VERSION ""

NS_ :

BS_:

BU_: pc mmc
VAL_TABLE_ DM_type_res 128 "Error" 36 "Four bytes type" 24 "Three bytes type" 16 "Two bytes type" 8 "One byte type" ;
VAL_TABLE_ DM_type_req 24 "Three bytes type" 32 "Four bytes type" 16 "Two bytes type" 8 "One byte type" ;

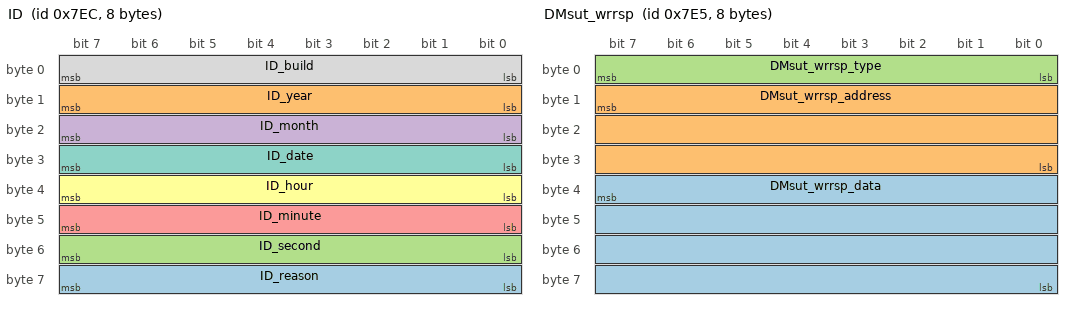
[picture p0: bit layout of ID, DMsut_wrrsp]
BO_ 2028 ID: 8 mmc
 SG_ ID_reason : 63|8@0+ (1,0) [0|0] ""  pc
 SG_ ID_year : 15|8@0+ (1,0) [0|0] ""  pc
 SG_ ID_second : 55|8@0+ (1,0) [0|0] ""  pc
 SG_ ID_month : 23|8@0+ (1,0) [0|0] ""  pc
 SG_ ID_minute : 47|8@0+ (1,0) [0|0] ""  pc
 SG_ ID_hour : 39|8@0+ (1,0) [0|0] ""  pc
 SG_ ID_date : 31|8@0+ (1,0) [0|0] ""  pc
 SG_ ID_build : 7|8@0+ (1,0) [0|0] ""  pc

BO_ 2021 DMsut_wrrsp: 8 mmc
 SG_ DMsut_wrrsp_data : 39|32@0+ (1,0) [0|4294967295] ""  pc
 SG_ DMsut_wrrsp_address : 15|24@0+ (1,0) [0|16777215] ""  pc
 SG_ DMsut_wrrsp_type : 7|8@0+ (1,0) [0|2] ""  pc

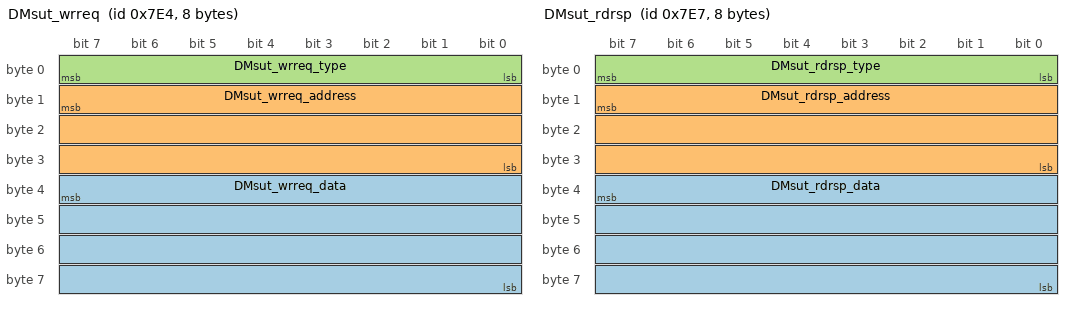
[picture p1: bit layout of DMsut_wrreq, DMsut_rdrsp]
BO_ 2020 DMsut_wrreq: 8 pc
 SG_ DMsut_wrreq_data : 39|32@0+ (1,0) [0|4294967295] ""  mmc
 SG_ DMsut_wrreq_address : 15|24@0+ (1,0) [0|16777215] ""  mmc
 SG_ DMsut_wrreq_type : 7|8@0+ (1,0) [0|2] ""  mmc

BO_ 2023 DMsut_rdrsp: 8 mmc
 SG_ DMsut_rdrsp_data : 39|32@0+ (1,0) [0|4294967295] ""  pc
 SG_ DMsut_rdrsp_address : 15|24@0+ (1,0) [0|16777215] ""  pc
 SG_ DMsut_rdrsp_type : 7|8@0+ (1,0) [0|2] ""  pc

BO_ 2022 DMsut_rdreq: 8 pc
 SG_ DMsut_rdreq_address : 15|24@0+ (1,0) [0|16777215] ""  mmc
 SG_ DMsut_rdreq_type : 7|8@0+ (1,0) [0|2] ""  mmc

EV_ EnvKlemme15: 0 [0|1] "" 0 1 DUMMY_NODE_VECTOR0 Vector__XXX;

BA_DEF_ BO_  "ExcludeFromUnitTesting" ENUM  "No","Yes";
BA_DEF_  "Manufacturer" STRING ;
BA_DEF_ BU_  "ILUsed" ENUM  "No","Yes";
BA_DEF_  "ILTxTimeout" INT 0 10000;
BA_DEF_ BO_  "GenMsgILSupport" ENUM  "No","Yes";
BA_DEF_  "NmBaseAddress" HEX 1024 1087;
BA_DEF_  "BusType" STRING ;
BA_DEF_ BO_  "GenMsgSendType" ENUM  "Cyclic","NotUsed","NotUsed","NotUsed","NotUsed","Cyclic","NotUsed","IfActive","NoMsgSendType","NotUsed","vector_leerstring";
BA_DEF_ SG_  "GenSigSendType" ENUM  "Cyclic","OnWrite","OnWriteWithRepetition","OnChange","OnChangeWithRepetition","IfActive","IfActiveWithRepetition","NoSigSendType","NotUsed","NotUsed","NotUsed","NotUsed","NotUsed";
BA_DEF_DEF_  "ExcludeFromUnitTesting" "No";
BA_DEF_DEF_  "Manufacturer" "McLaren";
BA_DEF_DEF_  "ILUsed" "Yes";
BA_DEF_DEF_  "ILTxTimeout" 30;
BA_DEF_DEF_  "GenMsgILSupport" "Yes";
BA_DEF_DEF_  "NmBaseAddress" 1024;
BA_DEF_DEF_  "BusType" "CAN";
BA_DEF_DEF_  "GenMsgSendType" "NoMsgSendType";
BA_DEF_DEF_  "GenSigSendType" "NoSigSendType";
BA_ "ExcludeFromUnitTesting" BO_ 2028 1;
BA_ "ExcludeFromUnitTesting" BO_ 2021 1;
BA_ "ExcludeFromUnitTesting" BO_ 2020 1;
BA_ "ExcludeFromUnitTesting" BO_ 2023 1;
BA_ "ExcludeFromUnitTesting" BO_ 2022 1;
BA_ "GenSigSendType" SG_ 2028 ID_build 1;
BA_ "GenSigSendType" SG_ 2021 DMsut_wrrsp_data 1;
BA_ "GenSigSendType" SG_ 2023 DMsut_rdrsp_data 1;
VAL_ 2021 DMsut_wrrsp_type 128 "Error" 36 "Four bytes type" 24 "Three bytes type" 16 "Two bytes type" 8 "One byte type" ;
VAL_ 2020 DMsut_wrreq_type 24 "Three bytes type" 32 "Four bytes type" 16 "Two bytes type" 8 "One byte type" ;
VAL_ 2023 DMsut_rdrsp_type 128 "Error" 36 "Four bytes type" 24 "Three bytes type" 16 "Two bytes type" 8 "One byte type" ;
VAL_ 2022 DMsut_rdreq_type 24 "Three bytes type" 32 "Four bytes type" 16 "Two bytes type" 8 "One byte type" ;
